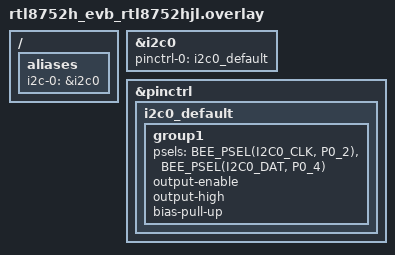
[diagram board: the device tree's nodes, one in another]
/*
 * Copyright (c) 2026, Realtek Semiconductor Corporation
 *
 * SPDX-License-Identifier: Apache-2.0
 */

/ {
	aliases {
		i2c-0 = &i2c0;
	};
};

&i2c0 {
	pinctrl-0 = <&i2c0_default>;
	pinctrl-names = "default";
	status = "okay";
};

&pinctrl {
	i2c0_default: i2c0_default {
		group1 {
			psels = <BEE_PSEL(I2C0_CLK, P0_2)>,
				<BEE_PSEL(I2C0_DAT, P0_4)>;
			output-enable;
			output-high;
			bias-pull-up;
		};
	};
};
